VERSION ""

NS_ :

BS_:

BU_: TelemLeader IMU_FR IMU_Back IMU_FL Suspension_FR Suspension_Back Suspension_FL Suspension_Specials Pitot_FR Pitot_FL WheelRPM_FR WheelRPM_FL RideHeight_FR RideHeight_Back RideHeight_FL Temp_Center GPS

BO_ 2147487744 TelemLeader_Center: 8 TelemLeader
 SG_ Timestamp : 0|16@1+ (1,0) [0|65535] "" Vector__XXX

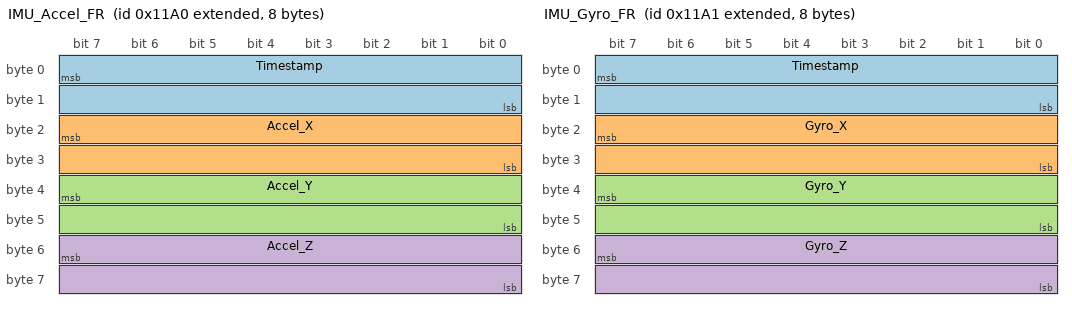
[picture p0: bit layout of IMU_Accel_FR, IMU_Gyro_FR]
BO_ 2147488160 IMU_Accel_FR: 8 IMU_FR
 SG_ Timestamp : 7|16@0+ (1,0) [0|65535] "" Vector__XXX
 SG_ Accel_X : 23|16@0+ (1,0) [0|65535] "" Vector__XXX
 SG_ Accel_Y : 39|16@0+ (1,0) [0|65535] "" Vector__XXX
 SG_ Accel_Z : 55|16@0+ (1,0) [0|65535] "" Vector__XXX

BO_ 2147488161 IMU_Gyro_FR: 8 IMU_FR
 SG_ Timestamp : 7|16@0+ (1,0) [0|65535] "" Vector__XXX
 SG_ Gyro_X : 23|16@0+ (1,0) [0|65535] "" Vector__XXX
 SG_ Gyro_Y : 39|16@0+ (1,0) [0|65535] "" Vector__XXX
 SG_ Gyro_Z : 55|16@0+ (1,0) [0|65535] "" Vector__XXX

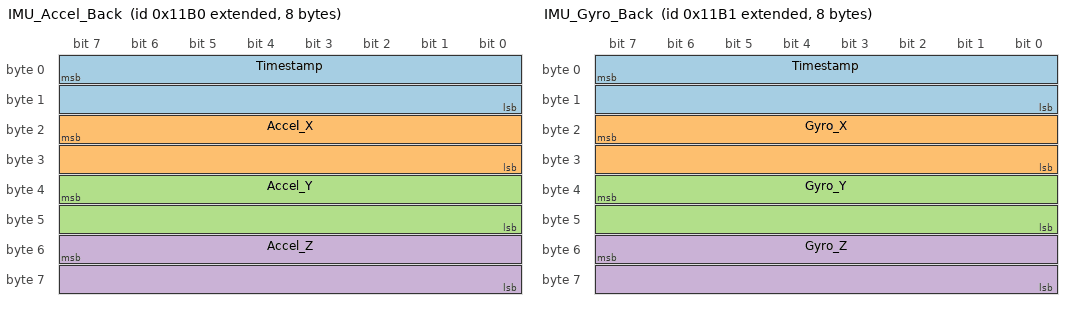
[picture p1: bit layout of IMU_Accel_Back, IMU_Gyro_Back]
BO_ 2147488176 IMU_Accel_Back: 8 IMU_Back
 SG_ Timestamp : 7|16@0+ (1,0) [0|65535] "" Vector__XXX
 SG_ Accel_X : 23|16@0+ (1,0) [0|65535] "" Vector__XXX
 SG_ Accel_Y : 39|16@0+ (1,0) [0|65535] "" Vector__XXX
 SG_ Accel_Z : 55|16@0+ (1,0) [0|65535] "" Vector__XXX

BO_ 2147488177 IMU_Gyro_Back: 8 IMU_Back
 SG_ Timestamp : 7|16@0+ (1,0) [0|65535] "" Vector__XXX
 SG_ Gyro_X : 23|16@0+ (1,0) [0|65535] "" Vector__XXX
 SG_ Gyro_Y : 39|16@0+ (1,0) [0|65535] "" Vector__XXX
 SG_ Gyro_Z : 55|16@0+ (1,0) [0|65535] "" Vector__XXX

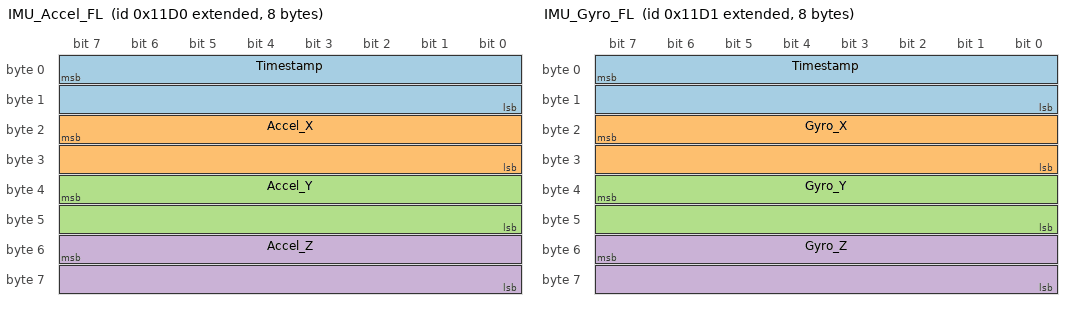
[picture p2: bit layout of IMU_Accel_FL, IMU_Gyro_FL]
BO_ 2147488208 IMU_Accel_FL: 8 IMU_FL
 SG_ Timestamp : 7|16@0+ (1,0) [0|65535] "" Vector__XXX
 SG_ Accel_X : 23|16@0+ (1,0) [0|65535] "" Vector__XXX
 SG_ Accel_Y : 39|16@0+ (1,0) [0|65535] "" Vector__XXX
 SG_ Accel_Z : 55|16@0+ (1,0) [0|65535] "" Vector__XXX

BO_ 2147488209 IMU_Gyro_FL: 8 IMU_FL
 SG_ Timestamp : 7|16@0+ (1,0) [0|65535] "" Vector__XXX
 SG_ Gyro_X : 23|16@0+ (1,0) [0|65535] "" Vector__XXX
 SG_ Gyro_Y : 39|16@0+ (1,0) [0|65535] "" Vector__XXX
 SG_ Gyro_Z : 55|16@0+ (1,0) [0|65535] "" Vector__XXX

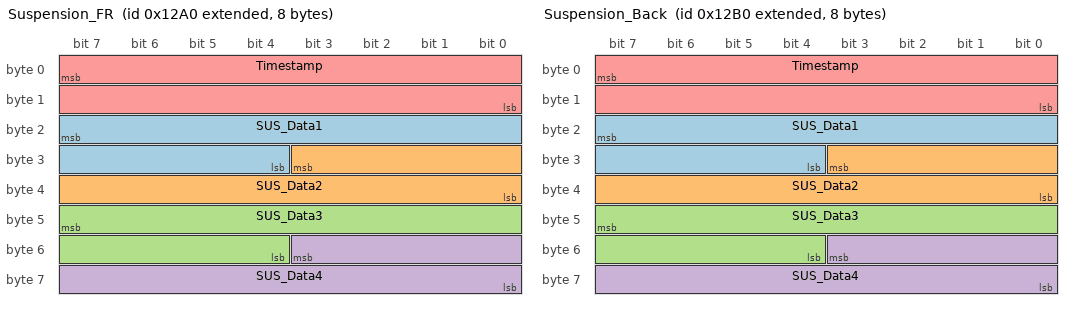
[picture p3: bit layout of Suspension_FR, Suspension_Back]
BO_ 2147488416 Suspension_FR: 8 Suspension_FR
 SG_ SUS_Data1 : 23|12@0+ (1,0) [0|4095] "" Vector__XXX
 SG_ SUS_Data2 : 27|12@0+ (1,0) [0|4095] "" Vector__XXX
 SG_ SUS_Data3 : 47|12@0+ (1,0) [0|4095] "" Vector__XXX
 SG_ SUS_Data4 : 51|12@0+ (1,0) [0|4095] "" Vector__XXX
 SG_ Timestamp : 7|16@0+ (1,0) [0|65535] "" Vector__XXX

BO_ 2147488432 Suspension_Back: 8 Suspension_Back
 SG_ SUS_Data1 : 23|12@0+ (1,0) [0|4095] "" Vector__XXX
 SG_ SUS_Data2 : 27|12@0+ (1,0) [0|4095] "" Vector__XXX
 SG_ SUS_Data3 : 47|12@0+ (1,0) [0|4095] "" Vector__XXX
 SG_ SUS_Data4 : 51|12@0+ (1,0) [0|4095] "" Vector__XXX
 SG_ Timestamp : 7|16@0+ (1,0) [0|65535] "" Vector__XXX

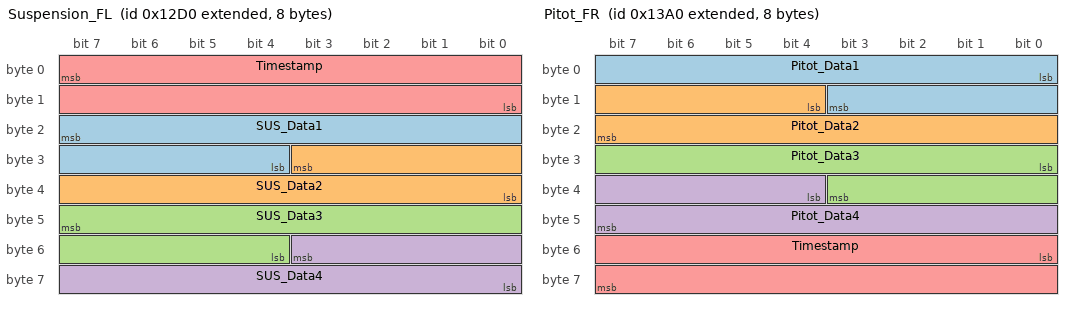
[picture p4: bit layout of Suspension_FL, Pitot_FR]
BO_ 2147488464 Suspension_FL: 8 Suspension_FL
 SG_ SUS_Data1 : 23|12@0+ (1,0) [0|4095] "" Vector__XXX
 SG_ SUS_Data2 : 27|12@0+ (1,0) [0|4095] "" Vector__XXX
 SG_ SUS_Data3 : 47|12@0+ (1,0) [0|4095] "" Vector__XXX
 SG_ SUS_Data4 : 51|12@0+ (1,0) [0|4095] "" Vector__XXX
 SG_ Timestamp : 7|16@0+ (1,0) [0|65535] "" Vector__XXX

BO_ 2147488672 Pitot_FR: 8 Pitot_FR
 SG_ Pitot_Data1 : 0|12@1+ (1,0) [0|4095] "" Vector__XXX
 SG_ Pitot_Data2 : 12|12@1+ (1,0) [0|4095] "" Vector__XXX
 SG_ Pitot_Data3 : 24|12@1+ (1,0) [0|4095] "" Vector__XXX
 SG_ Pitot_Data4 : 36|12@1+ (1,0) [0|4095] "" Vector__XXX
 SG_ Timestamp : 48|16@1+ (1,0) [0|65535] "" Vector__XXX

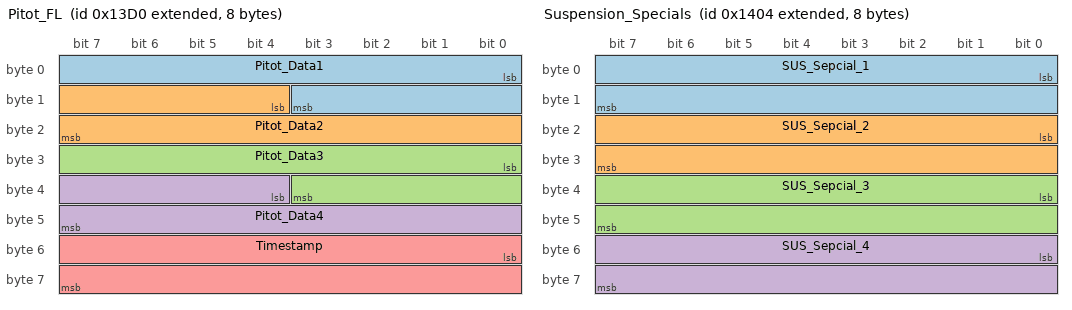
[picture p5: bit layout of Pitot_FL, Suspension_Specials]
BO_ 2147488720 Pitot_FL: 8 Pitot_FL
 SG_ Pitot_Data1 : 0|12@1+ (1,0) [0|4095] "" Vector__XXX
 SG_ Pitot_Data2 : 12|12@1+ (1,0) [0|4095] "" Vector__XXX
 SG_ Pitot_Data3 : 24|12@1+ (1,0) [0|4095] "" Vector__XXX
 SG_ Pitot_Data4 : 36|12@1+ (1,0) [0|4095] "" Vector__XXX
 SG_ Timestamp : 48|16@1+ (1,0) [0|65535] "" Vector__XXX

BO_ 2147488772 Suspension_Specials: 8 Suspension_Specials
 SG_ SUS_Sepcial_1 : 0|16@1+ (1,0) [0|65535] "" Vector__XXX
 SG_ SUS_Sepcial_2 : 16|16@1+ (1,0) [0|65535] "" Vector__XXX
 SG_ SUS_Sepcial_3 : 32|16@1+ (1,0) [0|65535] "" Vector__XXX
 SG_ SUS_Sepcial_4 : 48|16@1+ (1,0) [0|65535] "" Vector__XXX

BO_ 2147488928 WheelRPM_FR: 8 WheelRPM_FR
 SG_ RPM : 0|16@1+ (1,0) [0|65535] "" Vector__XXX
 SG_ Timestamp : 16|16@1+ (1,0) [0|65535] "" Vector__XXX

BO_ 2147488976 WheelRPM_FL: 8 WheelRPM_FL
 SG_ RPM : 0|16@1+ (1,0) [0|65535] "" Vector__XXX
 SG_ Timestamp : 16|16@1+ (1,0) [0|65535] "" Vector__XXX

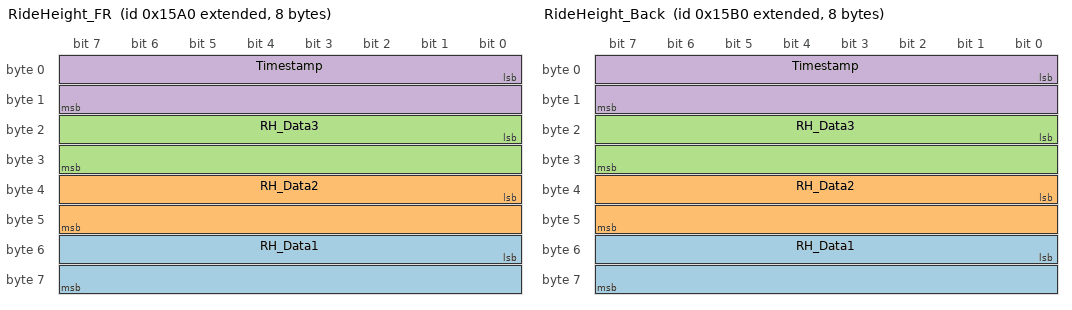
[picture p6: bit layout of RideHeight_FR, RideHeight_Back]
BO_ 2147489184 RideHeight_FR: 8 RideHeight_FR
 SG_ RH_Data1 : 48|16@1+ (1,0) [0|65535] "" Vector__XXX
 SG_ RH_Data2 : 32|16@1+ (1,0) [0|65535] "" Vector__XXX
 SG_ RH_Data3 : 16|16@1+ (1,0) [0|65535] "" Vector__XXX
 SG_ Timestamp : 0|16@1+ (1,0) [0|65535] "" Vector__XXX

BO_ 2147489200 RideHeight_Back: 8 RideHeight_Back
 SG_ RH_Data1 : 48|16@1+ (1,0) [0|65535] "" Vector__XXX
 SG_ RH_Data2 : 32|16@1+ (1,0) [0|65535] "" Vector__XXX
 SG_ RH_Data3 : 16|16@1+ (1,0) [0|65535] "" Vector__XXX
 SG_ Timestamp : 0|16@1+ (1,0) [0|65535] "" Vector__XXX

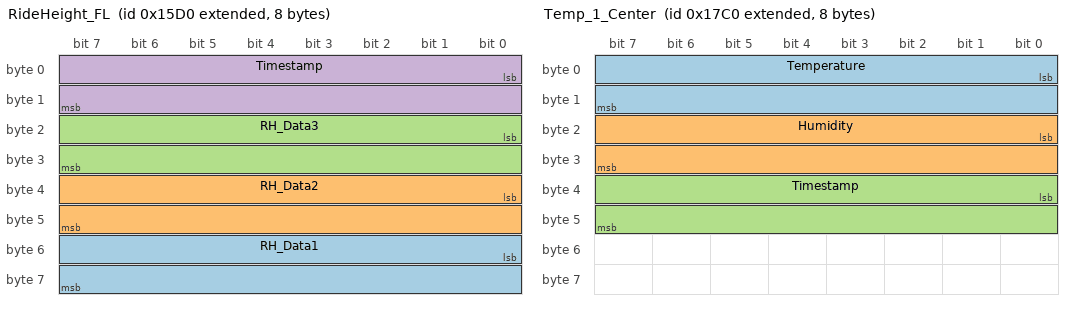
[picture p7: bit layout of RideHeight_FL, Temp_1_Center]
BO_ 2147489232 RideHeight_FL: 8 RideHeight_FL
 SG_ RH_Data1 : 48|16@1+ (1,0) [0|65535] "" Vector__XXX
 SG_ RH_Data2 : 32|16@1+ (1,0) [0|65535] "" Vector__XXX
 SG_ RH_Data3 : 16|16@1+ (1,0) [0|65535] "" Vector__XXX
 SG_ Timestamp : 0|16@1+ (1,0) [0|65535] "" Vector__XXX

BO_ 2147489536 GPS_Latitude: 4 GPS
 SG_ GPS_Latitude : 0|32@1+ (1,0) [0|4294967295] "" Vector__XXX

BO_ 2147489537 GPS_Longitude: 4 GPS
 SG_ GPS_Longitude : 0|32@1+ (1,0) [0|4294967295] "" Vector__XXX

BO_ 2147489538 GPS_Speed: 2 GPS
 SG_ GPS_Speed : 0|16@1+ (1,0) [0|65535] "" Vector__XXX

BO_ 2147489539 GPS_Status: 1 GPS
 SG_ GPS_Status : 0|8@1+ (1,0) [0|255] "" Vector__XXX

BO_ 2147489728 Temp_1_Center: 8 Temp_Center
 SG_ Temperature : 0|16@1+ (1,0) [0|65535] "" Vector__XXX
 SG_ Humidity : 16|16@1+ (1,0) [0|65535] "" Vector__XXX
 SG_ Timestamp : 32|16@1+ (1,0) [0|65535] "" Vector__XXX

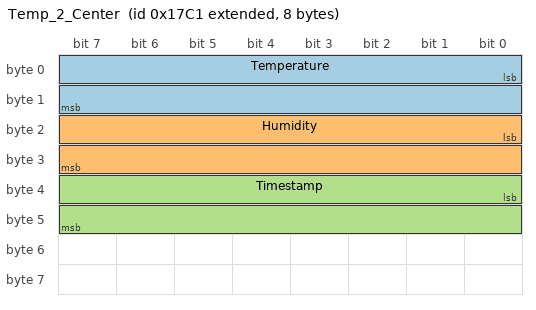
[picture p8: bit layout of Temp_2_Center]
BO_ 2147489729 Temp_2_Center: 8 Temp_Center
 SG_ Temperature : 0|16@1+ (1,0) [0|65535] "" Vector__XXX
 SG_ Humidity : 16|16@1+ (1,0) [0|65535] "" Vector__XXX
 SG_ Timestamp : 32|16@1+ (1,0) [0|65535] "" Vector__XXX

CM_ BO_ 4096 "Telem Leader Node. DAqCAN from Photon telem_rev1.dbc (UIPPlotsStaging); wire IDs = Photon base + 0x1000 (TelemLeader 0x1000). GPS telem IDs are Photon base then +0x1000 on wire.";
CM_ SG_ 4096 Timestamp "Wheel-Based Vehicle Speed: Speed of the vehicle as calculated from wheel or tailshaft speed.";

BA_DEF_  "DBName" STRING ;
BA_DEF_ BO_  "GenMsgSendType" ENUM  "Cyclic","Event","CyclicAndEvent","CyclicAndEventNoRepetition","None","Spontaneous";
BA_DEF_ BO_  "VFrameFormat" ENUM  "StandardCAN","ExtendedCAN","reserved","J1939PG","reserved","reserved","reserved","reserved","reserved","reserved","reserved","reserved","reserved","reserved","StandardCAN_FD","ExtendedCAN_FD";
BA_DEF_  "BusType" STRING ;
BA_DEF_DEF_  "DBName" "";
BA_DEF_DEF_  "GenMsgSendType" "Cyclic";
BA_DEF_DEF_  "VFrameFormat" "ExtendedCAN";
BA_DEF_DEF_  "BusType" "";
BA_ "BusType" "CAN";
BA_ "DBName" "DAqCAN";
